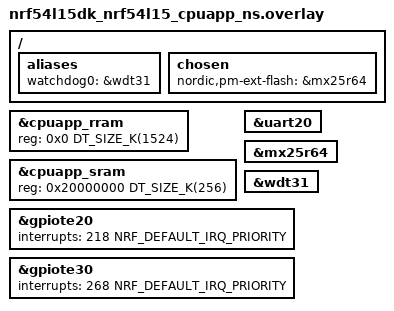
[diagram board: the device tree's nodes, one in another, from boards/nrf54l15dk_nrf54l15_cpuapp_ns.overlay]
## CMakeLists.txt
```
#
# Copyright (c) 2025 Nordic Semiconductor ASA
#
# SPDX-License-Identifier: LicenseRef-Nordic-5-Clause
#

cmake_minimum_required(VERSION 3.20.0)

find_package(Zephyr HINTS $ENV{ZEPHYR_BASE})

project(matter-manufacturer_specific)

include(${ZEPHYR_NRF_MODULE_DIR}/samples/matter/common/cmake/zap_helpers.cmake)
ncs_get_zap_parent_dir(ZAP_PARENT_DIR)

# Override zap-generated directory.
get_filename_component(CHIP_APP_ZAP_DIR ${ZAP_PARENT_DIR}/zap-generated REALPATH CACHE)

# Enable GNU STD support.
include(${ZEPHYR_CONNECTEDHOMEIP_MODULE_DIR}/config/nrfconnect/app/enable-gnu-std.cmake)

# NORDIC SDK APP START

# Include all source files that are located in the Matter common directory.
include(${ZEPHYR_NRF_MODULE_DIR}/samples/matter/common/cmake/source_common.cmake)

# Include Data Model utils
include(${ZEPHYR_NRF_MODULE_DIR}/samples/matter/common/cmake/data_model.cmake)

target_include_directories(app PRIVATE
  src
  ${ZAP_PARENT_DIR}
)

target_sources(app PRIVATE
  src/app_task.cpp
  src/zcl_callbacks.cpp
  src/main.cpp
  src/basic_information_extension.cpp
)

ncs_configure_data_model(
  EXTERNAL_CLUSTERS "NORDIC_DEV_KIT_CLUSTER"
)
# NORDIC SDK APP END
```

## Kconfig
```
#
# Copyright (c) 2025 Nordic Semiconductor
#
# SPDX-License-Identifier: LicenseRef-Nordic-5-Clause
#
mainmenu "Matter nRF Connect Manufacturer Specific Example Application"

# Sample configuration used for Thread networking
if OPENTHREAD

choice OPENTHREAD_NORDIC_LIBRARY_CONFIGURATION
	default OPENTHREAD_NORDIC_LIBRARY_MTD
endchoice

choice OPENTHREAD_DEVICE_TYPE
	default OPENTHREAD_MTD
endchoice

endif # OPENTHREAD

config CHIP_WIFI
	default y if BOARD_NRF7002DK_NRF5340_CPUAPP || SHIELD_NRF7002EB2
	select DEPRECATED if SOC_SERIES_NRF53X

source "$(ZEPHYR_CONNECTEDHOMEIP_MODULE_DIR)/config/nrfconnect/chip-module/Kconfig.features"
source "$(ZEPHYR_CONNECTEDHOMEIP_MODULE_DIR)/config/nrfconnect/chip-module/Kconfig.defaults"
source "$(ZEPHYR_NRF_MODULE_DIR)/samples/matter/common/src/Kconfig"
source "Kconfig.zephyr"
```

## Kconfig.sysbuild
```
#
# Copyright (c) 2025 Nordic Semiconductor ASA
#
# SPDX-License-Identifier: LicenseRef-Nordic-5-Clause
#

# This config has to be enabled manually for variants with shields, because sysbuild does not support it.
config WIFI_NRF70
	default y if BOARD_NRF7002DK

#### Radio core selection
config NRF_DEFAULT_IPC_RADIO
	default y

# Enable IEEE802.15.4 serialization to network core
# This config automatically pulls in the `overlay-802154.conf` in the ipc_radio image
config NETCORE_IPC_RADIO_IEEE802154
	default y if SOC_SERIES_NRF53X && !WIFI_NRF70

# Enable Bluetooth serialization to network core
# This config automatically pulls in the `overlay-bt_hci_ipc.conf` in the ipc_radio image
config NETCORE_IPC_RADIO_BT_HCI_IPC
	default y if (SOC_SERIES_NRF53X || SOC_SERIES_NRF54HX)

#### Bootloader
choice BOOTLOADER
	default BOOTLOADER_MCUBOOT
endchoice

if BOOTLOADER_MCUBOOT

#### DFU multi-image support
config DFU_MULTI_IMAGE_PACKAGE_BUILD
	default y

config DFU_MULTI_IMAGE_PACKAGE_APP
	default y

config PM_EXTERNAL_FLASH_MCUBOOT_SECONDARY
	default y

#### DFU network core configuration
if SOC_SERIES_NRF53X

choice MCUBOOT_MODE
	default MCUBOOT_MODE_OVERWRITE_ONLY
endchoice

choice BOOT_SIGNATURE_TYPE
	default BOOT_SIGNATURE_TYPE_RSA
endchoice

config SECURE_BOOT_NETCORE
	default y

config NETCORE_APP_UPDATE
	default y

config DFU_MULTI_IMAGE_PACKAGE_NET
	default y

endif # SOC_SERIES_NRF53X

if BOARD_NRF54L15DK || BOARD_NRF54LM20DK || BOARD_XIAO_NRF54LM20A

# Disable checking the external drivers for nRF54L15 and nRF54LM20 DKs.
config PM_OVERRIDE_EXTERNAL_DRIVER_CHECK
	default y

endif # BOARD_NRF54L15DK || BOARD_NRF54LM20DK || BOARD_XIAO_NRF54LM20A

# Mcuboot padding size is modified to 0x1000 in pm_static file.
if SOC_NRF54L10

config PM_MCUBOOT_PAD
	default 0x1000

endif # SOC_NRF54L10

endif # BOOTLOADER_MCUBOOT

# Store the Wi-Fi firmware patch on external flash by default for nRF5340 with nRF7002
if WIFI_NRF70 && SOC_NRF5340_CPUAPP

choice WIFI_PATCHES_EXT_FLASH_SUPPORT
	default WIFI_PATCHES_EXT_FLASH_STORE

endchoice

config DFU_MULTI_IMAGE_PACKAGE_WIFI_FW_PATCH
	default y

endif # WIFI_NRF70

#### Enable generating factory data
config MATTER_FACTORY_DATA_GENERATE
	default y if !BOARD_XIAO_NRF54LM20A

source "$(ZEPHYR_BASE)/share/sysbuild/Kconfig"
```

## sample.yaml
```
sample:
  description: Matter Manufacturer Specific sample
  name: Matter Manufacturer Specific
common:
  tags:
    - sysbuild
    - ci_samples_matter
tests:
  sample.matter.manufacturer_specific.debug:
    sysbuild: true
    build_only: true
    integration_platforms:
      - nrf52840dk/nrf52840
      - nrf5340dk/nrf5340/cpuapp
      - nrf54l15dk/nrf54l15/cpuapp
      - nrf54l15dk/nrf54l15/cpuapp/ns
      - nrf54l15dk/nrf54l10/cpuapp
      - nrf7002dk/nrf5340/cpuapp
      - nrf54lm20dk/nrf54lm20a/cpuapp
    platform_allow:
      - nrf52840dk/nrf52840
      - nrf5340dk/nrf5340/cpuapp
      - nrf54l15dk/nrf54l15/cpuapp
      - nrf54l15dk/nrf54l15/cpuapp/ns
      - nrf54l15dk/nrf54l10/cpuapp
      - nrf7002dk/nrf5340/cpuapp
      - nrf54lm20dk/nrf54lm20a/cpuapp
  sample.matter.manufacturer_specific.nrf7002eb2.debug:
    sysbuild: true
    build_only: true
    extra_args:
      - manufacturer_specific_SHIELD=nrf7002eb2
      - SB_CONFIG_WIFI_NRF70=y
    integration_platforms:
      - nrf54lm20dk/nrf54lm20a/cpuapp
    platform_allow:
      - nrf54lm20dk/nrf54lm20a/cpuapp
```

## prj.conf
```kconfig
#
# Copyright (c) 2025 Nordic Semiconductor ASA
#
# SPDX-License-Identifier: LicenseRef-Nordic-5-Clause
#

# This sample uses Kconfig.defaults to set options common for all
# samples. This file should contain only options specific for this sample
# or overrides of default values.

# Enable CHIP
CONFIG_CHIP=y
CONFIG_CHIP_PROJECT_CONFIG="src/chip_project_config.h"
CONFIG_CHIP_DEVICE_PRODUCT_NAME="Matter Manufacturer Specific"

# Configure ZAP file name
CONFIG_NCS_SAMPLE_MATTER_ZAP_FILE_PATH="${APPLICATION_CONFIG_DIR}/src/default_zap/manufacturer_specific.zap"

# 32768 == 0x8000 (example Product ID added temporaly,
# but it must be changed with proper PID from the list:
# https://github.com/project-chip/connectedhomeip/blob/482e6fd03196a6de45465a90003947ef4b86e0b1/docs/examples/discussion/PID_allocation_for_example_apps.md)
CONFIG_CHIP_DEVICE_PRODUCT_ID=32768
CONFIG_STD_CPP17=y

# Increase system workqueue stack size
CONFIG_SYSTEM_WORKQUEUE_STACK_SIZE=2048

# Enable Matter pairing automatically on application start.
CONFIG_CHIP_ENABLE_PAIRING_AUTOSTART=y

# Enable Matter extended announcement and increase duration to 1 hour.
CONFIG_CHIP_BLE_EXT_ADVERTISING=y
CONFIG_CHIP_BLE_ADVERTISING_DURATION=60

# Add support for LEDs and buttons on Nordic development kits
CONFIG_DK_LIBRARY=y

# Bluetooth Low Energy configuration
CONFIG_BT_DEVICE_NAME="MatterMS"

# Other settings
CONFIG_THREAD_NAME=y
CONFIG_MPU_STACK_GUARD=y
CONFIG_RESET_ON_FATAL_ERROR=n
CONFIG_CHIP_LIB_SHELL=y
CONFIG_NCS_SAMPLE_MATTER_TEST_SHELL=y

# Disable NFC onboarding
CONFIG_CHIP_NFC_ONBOARDING_PAYLOAD=n

# Reduce application size
CONFIG_USE_SEGGER_RTT=n

# Enable Factory Data feature
CONFIG_CHIP_FACTORY_DATA=y
CONFIG_CHIP_FACTORY_DATA_BUILD=y
```

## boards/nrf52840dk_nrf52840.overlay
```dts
/*
 * Copyright (c) 2025 Nordic Semiconductor ASA
 *
 * SPDX-License-Identifier: LicenseRef-Nordic-5-Clause
 */

/ {
	chosen {
		nordic,pm-ext-flash = &mx25r64;
	};
};

/* Disable unused peripherals to reduce power consumption */
&adc {
	status = "disabled";
};
&uart1 {
	status = "disabled";
};
&i2c0 {
	status = "disabled";
};
&pwm0 {
	status = "disabled";
};
&spi1 {
	status = "disabled";
};
&spi3 {
	status = "disabled";
};
&usbd {
	status = "disabled";
};
```

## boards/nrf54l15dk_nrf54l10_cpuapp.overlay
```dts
/*
 * Copyright (c) 2025 Nordic Semiconductor ASA
 *
 * SPDX-License-Identifier: LicenseRef-Nordic-5-Clause
 */

/ {
	aliases {
		/* Use watchdog wdt31 as the application watchdog */
		watchdog0 = &wdt31;
	};

	chosen {
		nordic,pm-ext-flash = &mx25r64;
	};
};

/* restore full RRAM and SRAM space - by default some parts are dedicated to FLRP */
&cpuapp_rram {
	reg = <0x0 DT_SIZE_K(1012)>;
};

&cpuapp_sram {
	reg = <0x20000000 DT_SIZE_K(192)>;
	ranges = <0x0 0x20000000  DT_SIZE_K(192)>;
};

/* TODO: re-enable HWFC once it's fixed */
&uart20 {
	/delete-property/ hw-flow-control;
};

&mx25r64 {
	status = "okay";
};

&wdt31 {
	status = "okay";
};
```

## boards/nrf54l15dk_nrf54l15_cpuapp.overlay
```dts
/*
 * Copyright (c) 2025 Nordic Semiconductor ASA
 *
 * SPDX-License-Identifier: LicenseRef-Nordic-5-Clause
 */

/ {
	aliases {
		/* Use watchdog wdt31 as the application watchdog */
		watchdog0 = &wdt31;
	};

	chosen {
		nordic,pm-ext-flash = &mx25r64;
	};
};

/* restore full RRAM and SRAM space - by default some parts are dedicated to FLRP */
&cpuapp_rram {
	reg = <0x0 DT_SIZE_K(1524)>;
};

&cpuapp_sram {
	reg = <0x20000000 DT_SIZE_K(256)>;
	ranges = <0x0 0x20000000  0x40000>;
};

/* TODO: re-enable HWFC once it's fixed */
&uart20 {
	/delete-property/ hw-flow-control;
};

&mx25r64 {
	status = "okay";
};

&wdt31 {
	status = "okay";
};
```

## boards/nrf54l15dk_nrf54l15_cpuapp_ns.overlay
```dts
/*
 * Copyright (c) 2025 Nordic Semiconductor ASA
 *
 * SPDX-License-Identifier: LicenseRef-Nordic-5-Clause
 */

/ {
	aliases {
		/* Use watchdog wdt31 as the application watchdog */
		watchdog0 = &wdt31;
	};

	chosen {
		nordic,pm-ext-flash = &mx25r64;
	};
};

/* restore full RRAM and SRAM space - by default some parts are dedicated to FLRP */
&cpuapp_rram {
	reg = <0x0 DT_SIZE_K(1524)>;
};

&cpuapp_sram {
	reg = <0x20000000 DT_SIZE_K(256)>;
	ranges = <0x0 0x20000000  0x40000>;
};

/* TODO: re-enable HWFC once it's fixed */
&uart20 {
	/delete-property/ hw-flow-control;
};

&mx25r64 {
	status = "okay";
};

&wdt31 {
	status = "okay";
};

/* Change IRQ ids to handle button interrupts.
 * The default values for nRF54L15 are 219 and 269,
 * but with TF-M they are reserved for the secure domain
 * (218 and 268 are reserved for the non-secure domain).
 */
&gpiote20 {
	interrupts = <218 NRF_DEFAULT_IRQ_PRIORITY>;
};

&gpiote30 {
	interrupts = <268 NRF_DEFAULT_IRQ_PRIORITY>;
};
```

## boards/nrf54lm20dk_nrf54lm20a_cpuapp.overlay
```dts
/*
 * Copyright (c) 2025 Nordic Semiconductor ASA
 *
 * SPDX-License-Identifier: LicenseRef-Nordic-5-Clause
 */

/ {
	chosen {
		nordic,pm-ext-flash = &mx25r64;
	};

	aliases {
		/* Use watchdog wdt31 as the application watchdog */
		watchdog0 = &wdt31;
	};
};

&mx25r64 {
	status = "okay";
};

&wdt31 {
	status = "okay";
};
```

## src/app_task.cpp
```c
/*
 * Copyright (c) 2025 Nordic Semiconductor ASA
 *
 * SPDX-License-Identifier: LicenseRef-Nordic-5-Clause
 */

#include "app_task.h"

#include "basic_information_extension.h"

#include "app/matter_init.h"
#include "app/task_executor.h"
#include "board/board.h"
#include "lib/core/CHIPError.h"
#include "lib/support/CodeUtils.h"

#include <app-common/zap-generated/attributes/Accessors.h>

#include <app/EventLogging.h>
#include <app/util/attribute-storage.h>
#include <setup_payload/OnboardingCodesUtil.h>

#include <data-model-providers/codegen/CodegenDataModelProvider.h>

#include <dk_buttons_and_leds.h>
#include <zephyr/logging/log.h>
#include <zephyr/random/random.h>

LOG_MODULE_DECLARE(app, CONFIG_CHIP_APP_LOG_LEVEL);

using namespace ::chip;
using namespace ::chip::app;
using namespace ::chip::DeviceLayer;

namespace
{
#define BUTTON2_MASK DK_BTN2_MSK
constexpr EndpointId kBasicInformationEndpointId = 0;
constexpr EndpointId kNordicDevKitEndpointId = 1;

RegisteredServerCluster<BasicInformationExtension> sBasicInformationExtension;
} /* namespace */

static void ButtonEventHandler(Nrf::ButtonState /* unused */, Nrf::ButtonMask has_changed)
{
	/* Handle button press */
	if (ConnectivityMgrImpl().IsIPv6NetworkProvisioned() && ConnectivityMgrImpl().IsIPv6NetworkEnabled() &&
	    BUTTON2_MASK & has_changed) {
		AppTask::Instance().UpdateNordicDevkitClusterState();
	}
}

void AppTask::UpdateNordicDevkitClusterState()
{
	SystemLayer().ScheduleLambda([] {
		Protocols::InteractionModel::Status status;
		Nrf::ButtonState button_state;

		dk_read_buttons(&button_state, nullptr);

		status = Clusters::NordicDevKit::Attributes::UserLED::Set(
			kNordicDevKitEndpointId, Nrf::GetBoard().GetLED(Nrf::DeviceLeds::LED2).GetState());

		if (status != Protocols::InteractionModel::Status::Success) {
			LOG_ERR("Updating NordicDevkit cluster failed: %x", to_underlying(status));
		}

		status = Clusters::NordicDevKit::Attributes::UserButton::Set(kNordicDevKitEndpointId,
									     BUTTON2_MASK & button_state);

		if (status != Protocols::InteractionModel::Status::Success) {
			LOG_ERR("Updating NordicDevkit cluster failed: %x", to_underlying(status));
		}

		for (auto endpoint : EnabledEndpointsWithServerCluster(Clusters::NordicDevKit::Id)) {
			/* If NordicDevKit cluster is implemented on this endpoint */
			Clusters::NordicDevKit::Events::UserButtonChanged::Type event;
			EventNumber eventNumber;

			if (CHIP_NO_ERROR != LogEvent(event, endpoint, eventNumber)) {
				ChipLogError(Zcl, "Failed to emit UserButtonChanged event");
			}
		}
	});
}

void AppTask::UpdateBasicInformationClusterState()
{
	SystemLayer().ScheduleLambda([] {
		DataModel::ActionReturnStatus status =
			sBasicInformationExtension.Cluster().SetRandomNumber(sys_rand16_get());

		if (status != CHIP_NO_ERROR) {
			ChipLogError(Zcl, "Updating Basic information cluster failed");
		}
	});
}

CHIP_ERROR AppTask::Init()
{
	/* Initialize Matter stack */
	ReturnErrorOnFailure(Nrf::Matter::PrepareServer());

	if (!Nrf::GetBoard().Init(ButtonEventHandler)) {
		LOG_ERR("User interface initialization failed.");
		return CHIP_ERROR_INCORRECT_STATE;
	}

	/* Register Matter event handler that controls the connectivity status LED based on the captured Matter network
	 * state. */
	ReturnErrorOnFailure(Nrf::Matter::RegisterEventHandler(Nrf::Board::DefaultMatterEventHandler, 0));

	return Nrf::Matter::StartServer();
}

CHIP_ERROR AppTask::StartApp()
{
	ReturnErrorOnFailure(Init());

	/* Replaces the registered BasicInformation cluster with a customized one that adds random number handling. */
	auto &registry = chip::app::CodegenDataModelProvider::Instance().Registry();

	ServerClusterInterface *interface =
		registry.Get({ kRootEndpointId, chip::app::Clusters::BasicInformation::Id });

	VerifyOrDie(interface != nullptr);

	registry.Unregister(interface);
	VerifyOrDie(registry.Register(sBasicInformationExtension.Registration()) == CHIP_NO_ERROR);

	while (true) {
		Nrf::DispatchNextTask();
	}

	return CHIP_NO_ERROR;
}
```

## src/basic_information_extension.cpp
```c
/*
 * Copyright (c) 2025 Nordic Semiconductor ASA
 *
 * SPDX-License-Identifier: LicenseRef-Nordic-5-Clause
 */

#include "basic_information_extension.h"

#include <app/EventLogging.h>
#include <app/util/attribute-storage.h>
#include <clusters/BasicInformation/Events.h>
#include <clusters/BasicInformation/Metadata.h>

using namespace chip;
using namespace chip::app;

constexpr AttributeId kRandomNumberAttributeId = 0x17;

constexpr DataModel::AttributeEntry kExtraAttributeMetadata[] = {
	{ kRandomNumberAttributeId,
	  {} /* qualities */,
	  Access::Privilege::kView /* readPriv */,
	  std::nullopt /* writePriv */ },
};

DataModel::ActionReturnStatus BasicInformationExtension::SetRandomNumber(int16_t newRandomNumber)
{
	mRandomNumber = newRandomNumber;

	Clusters::BasicInformation::Events::RandomNumberChanged::Type event;
	EventNumber eventNumber;

	for (auto endpoint : EnabledEndpointsWithServerCluster(Clusters::BasicInformation::Id)) {
		/* If Basic cluster is implemented on this endpoint */
		if (CHIP_NO_ERROR != LogEvent(event, endpoint, eventNumber)) {
			ChipLogError(Zcl, "Failed to emit RandomNumberChanged event");
		}
	}

	return CHIP_NO_ERROR;
}

DataModel::ActionReturnStatus BasicInformationExtension::ReadAttribute(const DataModel::ReadAttributeRequest &request,
								       AttributeValueEncoder &encoder)
{
	switch (request.path.mAttributeId) {
	case kRandomNumberAttributeId:
		return encoder.Encode(mRandomNumber);
	default:
		return chip::app::Clusters::BasicInformationCluster::ReadAttribute(request, encoder);
	}
}

DataModel::ActionReturnStatus BasicInformationExtension::WriteAttribute(const DataModel::WriteAttributeRequest &request,
									AttributeValueDecoder &decoder)
{
	switch (request.path.mAttributeId) {
	case kRandomNumberAttributeId:
		int16_t newRandomNumber;
		ReturnErrorOnFailure(decoder.Decode(newRandomNumber));
		return NotifyAttributeChangedIfSuccess(request.path.mAttributeId, SetRandomNumber(newRandomNumber));
	default:
		return chip::app::Clusters::BasicInformationCluster::WriteAttribute(request, decoder);
	}
}

CHIP_ERROR BasicInformationExtension::Attributes(const ConcreteClusterPath &path,
						 ReadOnlyBufferBuilder<DataModel::AttributeEntry> &builder)
{
	ReturnErrorOnFailure(builder.ReferenceExisting(kExtraAttributeMetadata));

	return chip::app::Clusters::BasicInformationCluster::Attributes(path, builder);
}

CHIP_ERROR BasicInformationExtension::AcceptedCommands(const ConcreteClusterPath &path,
						       ReadOnlyBufferBuilder<DataModel::AcceptedCommandEntry> &builder)
{
	/* The BasicInformationCluster does not have any commands, so it is not necessary to call the implementation of the base class. */
	static constexpr DataModel::AcceptedCommandEntry kAcceptedCommands[] = {
		Clusters::BasicInformation::Commands::GenerateRandom::kMetadataEntry
	};
	return builder.ReferenceExisting(kAcceptedCommands);
}

std::optional<DataModel::ActionReturnStatus>
BasicInformationExtension::InvokeCommand(const DataModel::InvokeRequest &request, chip::TLV::TLVReader &input_arguments,
					 CommandHandler *handler)
{
	switch (request.path.mCommandId) {
	case Clusters::BasicInformation::Commands::GenerateRandom::Id: {
		return SetRandomNumber(sys_rand16_get());
	}
	default:
		/* The BasicInformationCluster does not have any commands, so it is not necessary to call the implementation of the base class. */
		return Protocols::InteractionModel::Status::UnsupportedCommand;
	}
}
```

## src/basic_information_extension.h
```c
/*
 * Copyright (c) 2025 Nordic Semiconductor ASA
 *
 * SPDX-License-Identifier: LicenseRef-Nordic-5-Clause
 */

#pragma once

#include <app/clusters/basic-information/BasicInformationCluster.h>
#include <app/server-cluster/ServerClusterContext.h>
#include <app/server-cluster/ServerClusterInterface.h>

#include <zephyr/random/random.h>

class BasicInformationExtension : public chip::app::Clusters::BasicInformationCluster {
public:
	BasicInformationExtension() : mRandomNumber(sys_rand16_get()) {}

	chip::app::DataModel::ActionReturnStatus SetRandomNumber(int16_t newRandomNumber);

	/* Overrides the default BasicInformationCluster implementation. */
	chip::app::DataModel::ActionReturnStatus
	ReadAttribute(const chip::app::DataModel::ReadAttributeRequest &request,
		      chip::app::AttributeValueEncoder &encoder) override;

	chip::app::DataModel::ActionReturnStatus
	WriteAttribute(const chip::app::DataModel::WriteAttributeRequest &request,
		       chip::app::AttributeValueDecoder &decoder) override;

	CHIP_ERROR Attributes(const chip::app::ConcreteClusterPath &path,
			      chip::ReadOnlyBufferBuilder<chip::app::DataModel::AttributeEntry> &builder) override;

	CHIP_ERROR
	AcceptedCommands(const chip::app::ConcreteClusterPath &path,
			 chip::ReadOnlyBufferBuilder<chip::app::DataModel::AcceptedCommandEntry> &builder) override;

	std::optional<chip::app::DataModel::ActionReturnStatus>
	InvokeCommand(const chip::app::DataModel::InvokeRequest &request, chip::TLV::TLVReader &input_arguments,
		      chip::app::CommandHandler *handler) override;

private:
	int16_t mRandomNumber;
};
```

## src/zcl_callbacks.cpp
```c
/*
 * Copyright (c) 2025 Nordic Semiconductor ASA
 *
 * SPDX-License-Identifier: LicenseRef-Nordic-5-Clause
 */

#include <lib/support/logging/CHIPLogging.h>

#include "app_task.h"
#include "board/board.h"

#include <zap-generated/PluginApplicationCallbacks.h>
#include <app-common/zap-generated/callback.h>
#include <app-common/zap-generated/attributes/Accessors.h>
#include <app/ConcreteAttributePath.h>

using namespace ::chip;
using namespace ::chip::app;
using namespace ::chip::app::Clusters;
using namespace ::chip::app::Clusters::NordicDevKit::Commands;
using namespace ::chip::app::Clusters::BasicInformation::Commands;



bool emberAfNordicDevKitClusterSetLEDCallback(CommandHandler *commandObj,
						     const ConcreteCommandPath &commandPath,
						     const SetLED::DecodableType &commandData)
{
	switch (commandData.action) {
		case NordicDevKit::LEDActionEnum::kOff:
			Nrf::GetBoard().GetLED(Nrf::DeviceLeds::LED2).Set(false);
			break;
		case NordicDevKit::LEDActionEnum::kOn:
			Nrf::GetBoard().GetLED(Nrf::DeviceLeds::LED2).Set(true);
			break;
		case NordicDevKit::LEDActionEnum::kToggle:
			Nrf::GetBoard().GetLED(Nrf::DeviceLeds::LED2).Invert();
			break;
		default:
			commandObj->AddStatus(commandPath, Protocols::InteractionModel::Status::Failure);
			return true;
	}

	AppTask::Instance().UpdateNordicDevkitClusterState();
	commandObj->AddStatus(commandPath, Protocols::InteractionModel::Status::Success);

	return true;
}

void MatterNordicDevKitPluginServerInitCallback()
{
	/* Intentionally empty */
}

void MatterPostAttributeChangeCallback(const ConcreteAttributePath &attributePath, uint8_t type,
				       uint16_t size, uint8_t *value)
{
	/* Intentionally empty */
}

/** @brief NordicDevkit Cluster Init
 *
 * This function is called when a specific cluster is initialized. It gives the
 * application an opportunity to take care of cluster initialization procedures.
 * It is called exactly once for each endpoint where cluster is present.
 *
 * @param endpoint   Ver.: always
 *
 */
void emberAfNordicDevKitClusterInitCallback(EndpointId endpoint)
{
	Protocols::InteractionModel::Status status;
	bool storedValue;

	/* Read storedValue UserLED value */
	status = NordicDevKit::Attributes::UserLED::Get(endpoint, &storedValue);
	if (status == Protocols::InteractionModel::Status::Success) {
		/* Set actual state to the cluster state that was last persisted */
		Nrf::GetBoard().GetLED(Nrf::DeviceLeds::LED2).Set(storedValue);
	}
}

/** @brief Basic Information Cluster Init
 *
 * This function is called when a specific cluster is initialized. It gives the
 * application an opportunity to take care of cluster initialization procedures.
 * It is called exactly once for each endpoint where cluster is present.
 *
 * @param endpoint   Ver.: always
 *
 */
void emberAfBasicInformationClusterInitCallback(EndpointId /* unused */)
{
	AppTask::Instance().UpdateBasicInformationClusterState();
}
```
